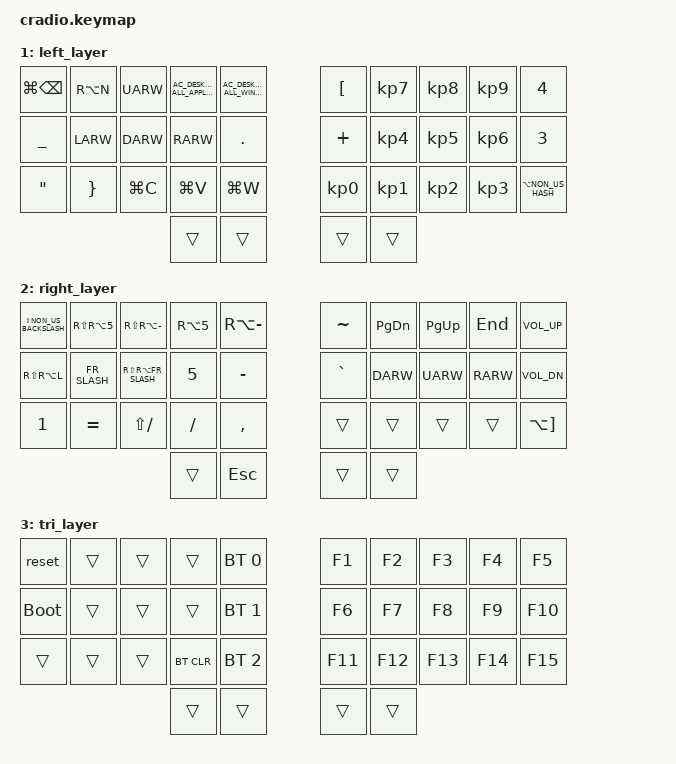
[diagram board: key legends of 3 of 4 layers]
// Copyright (c) 2022 The ZMK Contributors
// SPDX-License-Identifier: MIT

#include <behaviors.dtsi>
#include <dt-bindings/zmk/keys.h>
#include <dt-bindings/zmk/bt.h>
#include "keymap_french_mac_iso.h"

// Home row mods macro
#define HRML(k1,k2,k3,k4) &ht LSHFT k1  &ht LALT k2  &ht LCTRL k3  &ht LGUI k4
#define HRMR(k1,k2,k3,k4) &ht RGUI k1  &ht RCTRL k2  &ht RALT k3  &ht RSHFT k4
#define ACCENT_A(k1) &ht NUMBER_0 k1
#define ACCENT_E1(k1) &ht NUMBER_2 k1
#define ACCENT_E2(k1) &ht NUMBER_7 k1
#define ACCENT_U(k1) &ht FR_U_GRAVE k1
#define ACCENT_C(k1) &ht FR_C_CEDILLA k1

/ {
    behaviors {
        ht: hold_tap {
            label = "hold_tap";
            compatible = "zmk,behavior-hold-tap";
            #binding-cells = <2>;
            flavor = "tap-preferred";
            tapping-term-ms = <220>;
            quick-tap-ms = <150>;
            global-quick-tap;
            bindings = <&kp>, <&kp>;
        };
    };

    conditional_layers {
        compatible = "zmk,conditional-layers";
        tri_layer {
            if-layers = <1 2>;
            then-layer = <3>;
        };
    };

//https://zmk.dev/docs/codes
//M -> SEMICOLON
//é -> FR_E_ACUTE
//: -> DOT
//< -> GRAVE
//> -> TILDE

    keymap {
        compatible = "zmk,keymap";
        default_layer {
            bindings = <
        //╭──────────┬──────────┬──────────┬──────────┬──────────╮   ╭──────────┬──────────┬──────────┬──────────┬──────────╮
        //│  Q       │  W       │  E       │  R       │  T       │   │  Y       │  U       │  I       │  O       │  P       │
            ACCENT_A(Q)  &kp W   ACCENT_E1(E) ACCENT_E2(R)   &kp T     &kp Y    ACCENT_U(U)    &kp I      &kp O      &kp P
        //├──────────┼──────────┼──────────┼──────────┼──────────┤   ├──────────┼──────────┼──────────┼──────────┼──────────┤
        //│  A       │  S       │  D       │  F       │  G       │   │  H       │  J       │  K       │  L       │    M     │
            HRML(A,        S,         D,         F)     &kp G          &kp H      HRMR(J,        K,         L,    SEMICOLON)
        //├──────────┼──────────┼──────────┼──────────┼──────────┤   ├──────────┼──────────┼──────────┼──────────┼──────────┤
        //│  Z       │  X       │  C       │  V       │  B       │   │  N       │   .      │   ,      │   ?      │   !      │
            &kp Z      &kp X    ACCENT_C(C)   &kp V      &kp B          &kp N     &kp FR_DOT &kp FR_COMMA &kp FR_QUESTION &kp NUMBER_8
        //╰──────────┴──────────┴──────────┼──────────┼──────────┤   ├──────────┼──────────┼──────────┴──────────┴──────────╯
                                            &lt 1 TAB  &lt 2 ENTER     &kp SPACE  &kp BSPC
        //                                 ╰──────────┴──────────╯   ╰──────────┴──────────╯
            >;
        };

        left_layer {
            bindings = <
        //╭──────────┬──────────┬──────────┬──────────┬──────────╮   ╭──────────┬──────────┬──────────┬──────────┬──────────╮
        //│   Delete │    ~     │  UP      │  ALLApp  │ALLWindows│   │  ^       │  7       │  8       │  9       │  -       │
            &kp LG(BSPC) &kp RA(N)   &kp UARW   &kp C_AC_DESKTOP_SHOW_ALL_APPLICATIONS   &kp C_AC_DESKTOP_SHOW_ALL_WINDOWS      &kp LBKT  &kp KP_N7  &kp KP_N8  &kp KP_N9   &kp NUMBER_4
        //├──────────┼──────────┼──────────┼──────────┼──────────┤   ├──────────┼──────────┼──────────┼──────────┼──────────┤
        //│  °       │  LEFT    │  DOWN    │  RIGHT   │  :       │   │  _       │  4       │  5       │  6       │  "       │
            &kp UNDER   &kp LARW   &kp DARW   &kp RARW   &kp DOT       &kp PLUS &kp KP_N4  &kp KP_N5  &kp KP_N6   &kp NUMBER_3
        //├──────────┼──────────┼──────────┼──────────┼──────────┤   ├──────────┼──────────┼──────────┼──────────┼──────────┤
        //│    %     │    *     │          │          │          │   │  0       │  1       │  2       │  3       │    @     │
            &kp DQT    &kp RBRC  &kp LG(C) &kp LG(V)   &kp LG(W)       &kp KP_N0  &kp KP_N1  &kp KP_N2  &kp KP_N3  &kp LA(NON_US_HASH)
        //╰──────────┴──────────┴──────────┼──────────┼──────────┤   ├──────────┼──────────┼──────────┴──────────┴──────────╯
                                             &trans     &trans         &trans     &trans
        //                                 ╰──────────┴──────────╯   ╰──────────┴──────────╯
            >;
        };

        right_layer {
            bindings = <
        //╭──────────┬──────────┬──────────┬──────────┬──────────╮   ╭──────────┬──────────┬──────────┬──────────┬──────────╮
        //│    #     │  [       │  ]       │  {       │     }    │   │ HOME     │ PAGE DN  │ PAGE UP  │ END      │  :       │
            &kp LS(NON_US_BACKSLASH)   &kp RS(RA(N5))  &kp RS(RA(MINUS)) &kp RA(N5)  &kp RA(MINUS)        &kp TILDE   &kp PG_DN  &kp PG_UP  &kp END    &kp C_VOL_UP
        //├──────────┼──────────┼──────────┼──────────┼──────────┤   ├──────────┼──────────┼──────────┼──────────┼──────────┤
        //│    |     │  4       │  5       │  (       │    )     │   │ LEFT     │ DOWN     │ UP       │ RIGHT    │  ;       │
            &kp RS(RA(L)) &kp FR_SLASH  &kp RS(RA(FR_SLASH)) &kp N5 &kp MINUS       &kp GRAVE   &kp DARW   &kp UARW   &kp RARW   &kp C_VOL_DN
        //├──────────┼──────────┼──────────┼──────────┼──────────┤   ├──────────┼──────────┼──────────┼──────────┼──────────┤
        //│    &     │  -       │  +       │  =       │  ;       │   │          │          │          │          │     €    │
           &kp NUMBER_1 &kp EQUAL &kp LS(SLASH) &kp SLASH &kp COMMA      &trans    &trans     &trans    &trans     &kp LA(RBKT)
        //╰──────────┴──────────┴──────────┼──────────┼──────────┤   ├──────────┼──────────┼──────────┴──────────┴──────────╯
                                             &trans     &kp ESC        &trans     &trans
        //                                 ╰──────────┴──────────╯   ╰──────────┴──────────╯
            >;
        };

        tri_layer {
            bindings = <
        //╭──────────┬──────────┬──────────┬──────────┬──────────╮   ╭──────────┬──────────┬──────────┬──────────┬──────────╮
        //│ RESET    │          │          │          │PROFILE 0 │   │          │          │          │          │          │
            &reset     &trans     &trans     &trans    &bt BT_SEL 0    &kp F1     &kp F2     &kp F3     &kp F4     &kp F5
        //├──────────┼──────────┼──────────┼──────────┼──────────┤   ├──────────┼──────────┼──────────┼──────────┼──────────┤
        //│BOOTLOADER│          │          │          │PROFILE 1 │   │          │          │          │          │          │
          &bootloader  &trans     &trans     &trans    &bt BT_SEL 1    &kp F6     &kp F7     &kp F8     &kp F9     &kp F10
        //├──────────┼──────────┼──────────┼──────────┼──────────┤   ├──────────┼──────────┼──────────┼──────────┼──────────┤
        //│          │          │          │ CLEAR BT │PROFILE 2 │   │          │          │          │          │          │
            &trans     &trans     &trans    &bt BT_CLR &bt BT_SEL 2    &kp F11    &kp F12    &kp F13    &kp F14    &kp F15
        //╰──────────┴──────────┴──────────┼──────────┼──────────┤   ├──────────┼──────────┼──────────┴──────────┴──────────╯
                                             &trans     &trans         &trans     &trans
        //                                 ╰──────────┴──────────╯   ╰──────────┴──────────╯
            >;
        };
    };
};

&kscan0 {
	input-gpios
		= <&pro_micro  7 (GPIO_ACTIVE_LOW | GPIO_PULL_UP)>
		, <&pro_micro 18 (GPIO_ACTIVE_LOW | GPIO_PULL_UP)>
		, <&pro_micro 19 (GPIO_ACTIVE_LOW | GPIO_PULL_UP)>
		, <&pro_micro 20 (GPIO_ACTIVE_LOW | GPIO_PULL_UP)>
		, <&pro_micro 21 (GPIO_ACTIVE_LOW | GPIO_PULL_UP)>
		, <&pro_micro 15 (GPIO_ACTIVE_LOW | GPIO_PULL_UP)>
		, <&gpio1 7 (GPIO_ACTIVE_LOW | GPIO_PULL_UP)>/* RC(0,6) was 14*/
		, <&gpio1 2 (GPIO_ACTIVE_LOW | GPIO_PULL_UP)>/* RC(0,7) was 16*/
		, <&pro_micro 10 (GPIO_ACTIVE_LOW | GPIO_PULL_UP)>
		, <&pro_micro  0 (GPIO_ACTIVE_LOW | GPIO_PULL_UP)>/* RC(0,9) was 1*/
		, <&pro_micro  2 (GPIO_ACTIVE_LOW | GPIO_PULL_UP)>
		, <&pro_micro  3 (GPIO_ACTIVE_LOW | GPIO_PULL_UP)>
		, <&pro_micro  4 (GPIO_ACTIVE_LOW | GPIO_PULL_UP)>
		, <&pro_micro  5 (GPIO_ACTIVE_LOW | GPIO_PULL_UP)>
		, <&pro_micro  6 (GPIO_ACTIVE_LOW | GPIO_PULL_UP)>
		, <&pro_micro  8 (GPIO_ACTIVE_LOW | GPIO_PULL_UP)>
		, <&pro_micro  9 (GPIO_ACTIVE_LOW | GPIO_PULL_UP)>
		;
};
